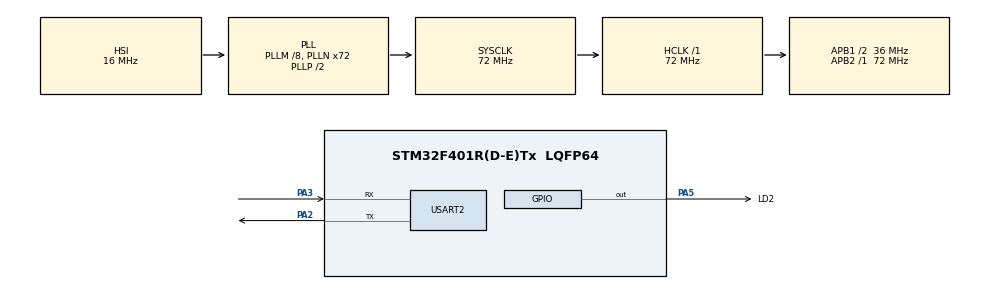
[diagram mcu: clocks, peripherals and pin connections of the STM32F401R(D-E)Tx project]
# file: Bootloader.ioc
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Mcu.Family=STM32F4
Mcu.Name=STM32F401R(D-E)Tx
Mcu.Package=LQFP64
NVIC.PriorityGroup=NVIC_PRIORITYGROUP_4
PA2.Mode=Asynchronous
PA2.Signal=USART2_TX
PA3.Mode=Asynchronous
PA3.Signal=USART2_RX
PA5.GPIO_Label=LD2
PA5.Signal=GPIO_Output
ProjectManager.HeapSize=0x200
ProjectManager.StackSize=0x400
ProjectManager.TargetToolchain=STM32CubeIDE
RCC.48MHZClocksFreq_Value=36000000
RCC.AHBFreq_Value=72000000
RCC.APB1CLKDivider=RCC_HCLK_DIV2
RCC.APB1Freq_Value=36000000
RCC.APB1TimFreq_Value=72000000
RCC.APB2Freq_Value=72000000
RCC.APB2TimFreq_Value=72000000
RCC.CortexFreq_Value=72000000
RCC.HCLKFreq_Value=72000000
RCC.HSE_VALUE=25000000
RCC.HSI_VALUE=16000000
RCC.LSE_VALUE=32768
RCC.PLLM=8
RCC.PLLN=72
RCC.SYSCLKFreq_VALUE=72000000
RCC.SYSCLKSource=RCC_SYSCLKSOURCE_PLLCLK
RCC.VCOOutputFreq_Value=144000000
USART2.VirtualMode=VM_ASYNC
board=custom

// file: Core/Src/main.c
/* USER CODE BEGIN Header */
/**
  ******************************************************************************
  * @file           : main.c
  * @brief          : Main program body
  ******************************************************************************
  * @attention
  *
  * Copyright (c) 2025 STMicroelectronics.
  * All rights reserved.
  *
  * This software is licensed under terms that can be found in the LICENSE file
  * in the root directory of this software component.
  * If no LICENSE file comes with this software, it is provided AS-IS.
  *
  ******************************************************************************
  */
/* USER CODE END Header */
#include "main.h"

/* USER CODE BEGIN Includes */
#include "stdio.h"
/* USER CODE END Includes */

/* USER CODE BEGIN PTD */
#define FLASH_APP_ADDR 	0x8008000
/* USER CODE END PTD */

UART_HandleTypeDef huart2;

/* USER CODE BEGIN PV */

_Bool Firmware_Completed_EOF=0;
uint32_t Current_Address= 0;
uint32_t Previous_Address =0;
uint16_t CRC_VALUE=0;
uint8_t Length =0;
uint8_t Uart_Rx[200];
uint8_t crc_data[2];
static FLASH_EraseInitTypeDef Erase;
/* Table of CRC values for high-order byte */
static const uint8_t table_crc_hi[] = {
    0x00, 0xC1, 0x81, 0x40, 0x01, 0xC0, 0x80, 0x41, 0x01, 0xC0,
    0x80, 0x41, 0x00, 0xC1, 0x81, 0x40, 0x01, 0xC0, 0x80, 0x41,
    0x00, 0xC1, 0x81, 0x40, 0x00, 0xC1, 0x81, 0x40, 0x01, 0xC0,
    0x80, 0x41, 0x01, 0xC0, 0x80, 0x41, 0x00, 0xC1, 0x81, 0x40,
    0x00, 0xC1, 0x81, 0x40, 0x01, 0xC0, 0x80, 0x41, 0x00, 0xC1,
    0x81, 0x40, 0x01, 0xC0, 0x80, 0x41, 0x01, 0xC0, 0x80, 0x41,
    0x00, 0xC1, 0x81, 0x40, 0x01, 0xC0, 0x80, 0x41, 0x00, 0xC1,
    0x81, 0x40, 0x00, 0xC1, 0x81, 0x40, 0x01, 0xC0, 0x80, 0x41,
    0x00, 0xC1, 0x81, 0x40, 0x01, 0xC0, 0x80, 0x41, 0x01, 0xC0,
    0x80, 0x41, 0x00, 0xC1, 0x81, 0x40, 0x00, 0xC1, 0x81, 0x40,
    0x01, 0xC0, 0x80, 0x41, 0x01, 0xC0, 0x80, 0x41, 0x00, 0xC1,
    0x81, 0x40, 0x01, 0xC0, 0x80, 0x41, 0x00, 0xC1, 0x81, 0x40,
    0x00, 0xC1, 0x81, 0x40, 0x01, 0xC0, 0x80, 0x41, 0x01, 0xC0,
    0x80, 0x41, 0x00, 0xC1, 0x81, 0x40, 0x00, 0xC1, 0x81, 0x40,
    0x01, 0xC0, 0x80, 0x41, 0x00, 0xC1, 0x81, 0x40, 0x01, 0xC0,
    0x80, 0x41, 0x01, 0xC0, 0x80, 0x41, 0x00, 0xC1, 0x81, 0x40,
    0x00, 0xC1, 0x81, 0x40, 0x01, 0xC0, 0x80, 0x41, 0x01, 0xC0,
    0x80, 0x41, 0x00, 0xC1, 0x81, 0x40, 0x01, 0xC0, 0x80, 0x41,
    0x00, 0xC1, 0x81, 0x40, 0x00, 0xC1, 0x81, 0x40, 0x01, 0xC0,
    0x80, 0x41, 0x00, 0xC1, 0x81, 0x40, 0x01, 0xC0, 0x80, 0x41,
    0x01, 0xC0, 0x80, 0x41, 0x00, 0xC1, 0x81, 0x40, 0x01, 0xC0,
    0x80, 0x41, 0x00, 0xC1, 0x81, 0x40, 0x00, 0xC1, 0x81, 0x40,
    0x01, 0xC0, 0x80, 0x41, 0x01, 0xC0, 0x80, 0x41, 0x00, 0xC1,
    0x81, 0x40, 0x00, 0xC1, 0x81, 0x40, 0x01, 0xC0, 0x80, 0x41,
    0x00, 0xC1, 0x81, 0x40, 0x01, 0xC0, 0x80, 0x41, 0x01, 0xC0,
    0x80, 0x41, 0x00, 0xC1, 0x81, 0x40
};

/* Table of CRC values for low-order byte */
static const uint8_t table_crc_lo[] = {
    0x00, 0xC0, 0xC1, 0x01, 0xC3, 0x03, 0x02, 0xC2, 0xC6, 0x06,
    0x07, 0xC7, 0x05, 0xC5, 0xC4, 0x04, 0xCC, 0x0C, 0x0D, 0xCD,
    0x0F, 0xCF, 0xCE, 0x0E, 0x0A, 0xCA, 0xCB, 0x0B, 0xC9, 0x09,
    0x08, 0xC8, 0xD8, 0x18, 0x19, 0xD9, 0x1B, 0xDB, 0xDA, 0x1A,
    0x1E, 0xDE, 0xDF, 0x1F, 0xDD, 0x1D, 0x1C, 0xDC, 0x14, 0xD4,
    0xD5, 0x15, 0xD7, 0x17, 0x16, 0xD6, 0xD2, 0x12, 0x13, 0xD3,
    0x11, 0xD1, 0xD0, 0x10, 0xF0, 0x30, 0x31, 0xF1, 0x33, 0xF3,
    0xF2, 0x32, 0x36, 0xF6, 0xF7, 0x37, 0xF5, 0x35, 0x34, 0xF4,
    0x3C, 0xFC, 0xFD, 0x3D, 0xFF, 0x3F, 0x3E, 0xFE, 0xFA, 0x3A,
    0x3B, 0xFB, 0x39, 0xF9, 0xF8, 0x38, 0x28, 0xE8, 0xE9, 0x29,
    0xEB, 0x2B, 0x2A, 0xEA, 0xEE, 0x2E, 0x2F, 0xEF, 0x2D, 0xED,
    0xEC, 0x2C, 0xE4, 0x24, 0x25, 0xE5, 0x27, 0xE7, 0xE6, 0x26,
    0x22, 0xE2, 0xE3, 0x23, 0xE1, 0x21, 0x20, 0xE0, 0xA0, 0x60,
    0x61, 0xA1, 0x63, 0xA3, 0xA2, 0x62, 0x66, 0xA6, 0xA7, 0x67,
    0xA5, 0x65, 0x64, 0xA4, 0x6C, 0xAC, 0xAD, 0x6D, 0xAF, 0x6F,
    0x6E, 0xAE, 0xAA, 0x6A, 0x6B, 0xAB, 0x69, 0xA9, 0xA8, 0x68,
    0x78, 0xB8, 0xB9, 0x79, 0xBB, 0x7B, 0x7A, 0xBA, 0xBE, 0x7E,
    0x7F, 0xBF, 0x7D, 0xBD, 0xBC, 0x7C, 0xB4, 0x74, 0x75, 0xB5,
    0x77, 0xB7, 0xB6, 0x76, 0x72, 0xB2, 0xB3, 0x73, 0xB1, 0x71,
    0x70, 0xB0, 0x50, 0x90, 0x91, 0x51, 0x93, 0x53, 0x52, 0x92,
    0x96, 0x56, 0x57, 0x97, 0x55, 0x95, 0x94, 0x54, 0x9C, 0x5C,
    0x5D, 0x9D, 0x5F, 0x9F, 0x9E, 0x5E, 0x5A, 0x9A, 0x9B, 0x5B,
    0x99, 0x59, 0x58, 0x98, 0x88, 0x48, 0x49, 0x89, 0x4B, 0x8B,
    0x8A, 0x4A, 0x4E, 0x8E, 0x8F, 0x4F, 0x8D, 0x4D, 0x4C, 0x8C,
    0x44, 0x84, 0x85, 0x45, 0x87, 0x47, 0x46, 0x86, 0x82, 0x42,
    0x43, 0x83, 0x41, 0x81, 0x80, 0x40
};
/* USER CODE END PV */

void SystemClock_Config(void);
static void MX_GPIO_Init(void);
static void MX_USART2_UART_Init(void);
/* USER CODE BEGIN PFP */
typedef void (*pFunction)(void);

#ifdef __GNUC__
#define PUTCHAR_PROTOTYPE int __io_putchar(int ch)
#else
#define PUTCHAR_PROTOTYPE int fputc(int ch, FILE *f)
#endif

PUTCHAR_PROTOTYPE
{
  HAL_UART_Transmit(&huart2, (uint8_t *)&ch, 1, HAL_MAX_DELAY);
  return ch;
}
/* USER CODE END PFP */

/* USER CODE BEGIN 0 */
void go2App(void)
{
	uint32_t JumpAddress;
	pFunction Jump_To_Application;

	printf("Bootloader Start \r\n");

	//Check if there is something installed in the app Flash Region
	if(((*(uint32_t * )FLASH_APP_ADDR)& 0x2FFE0000) == 0x20000000)
	{
		printf("App Start..\r\n");
		HAL_Delay(100);
		// jump to the application
		JumpAddress = *(uint32_t*)( FLASH_APP_ADDR + 4);
		Jump_To_Application = (pFunction) JumpAddress;
		//Initialize application's stack pointer
		__set_MSP(*(uint32_t *)FLASH_APP_ADDR);
		Jump_To_Application();
	}
	else{
		//there is no application is installed
		printf("No APP Found \r\n");
	}
}

uint32_t crc16(uint8_t *buffer, uint16_t buffer_length)
{
    uint8_t crc_hi = 0xFF; /* high CRC byte initialized */
    uint8_t crc_lo = 0xFF; /* low CRC byte initialized */
    uint16_t i; /* will index into CRC lookup */

    /* pass through message buffer */
    while (buffer_length--) {
        i = crc_lo ^ *buffer++; /* calculate the CRC  */
        crc_lo = crc_hi ^ table_crc_hi[i];
        crc_hi = table_crc_lo[i];
    }

    return (crc_hi << 8 | crc_lo);
}

static uint32_t GetSector(uint32_t Address)
{
  uint32_t sector = 0;

  if((Address < 0x08003FFF) && (Address >= 0x08000000))
  {
    sector = FLASH_SECTOR_0;
  }
  else if((Address < 0x08007FFF) && (Address >= 0x08004000))
  {
    sector = FLASH_SECTOR_1;
  }
  else if((Address < 0x0800BFFF) && (Address >= 0x08008000))
  {
    sector = FLASH_SECTOR_2;
  }
  else if((Address < 0x0800FFFF) && (Address >= 0x0800C000))
  {
    sector = FLASH_SECTOR_3;
  }
  else if((Address < 0x0801FFFF) && (Address >= 0x08010000))
  {
    sector = FLASH_SECTOR_4;
  }
  else if((Address < 0x0803FFFF) && (Address >= 0x08020000))
  {
    sector = FLASH_SECTOR_5;
  }
  else if((Address < 0x0805FFFF) && (Address >= 0x08040000))
  {
    sector = FLASH_SECTOR_6;
  }
  else if((Address < 0x0807FFFF) && (Address >= 0x08060000))
  {
    sector = FLASH_SECTOR_7;
  }
  return sector;
}

uint32_t Flash_Write_Data (uint32_t StartSectorAddress, uint32_t *Data, uint16_t numberofwords)
{

	static FLASH_EraseInitTypeDef EraseInitStruct;
	uint32_t SECTORError;
	int sofar=0;

	 /* Unlock the Flash to enable the flash control register access *************/
	  HAL_FLASH_Unlock();

	  /* Erase the user Flash area */

	  /* Get the number of sector to erase from 1st sector */

//	  uint32_t StartSector = GetSector(StartSectorAddress);
//	  uint32_t EndSectorAddress = StartSectorAddress + numberofwords*4;
//	  uint32_t EndSector = GetSector(EndSectorAddress);
//
//	  /* Fill EraseInit structure*/
//	  EraseInitStruct.TypeErase     = FLASH_TYPEERASE_SECTORS;
//	  EraseInitStruct.VoltageRange  = FLASH_VOLTAGE_RANGE_3;
//	  EraseInitStruct.Sector        = StartSector;
//	  EraseInitStruct.NbSectors     = (EndSector - StartSector) + 1;
//
//	  /* Note: If an erase operation in Flash memory also concerns data in the data or instruction cache,
//	     you have to make sure that these data are rewritten before they are accessed during code
//	     execution. If this cannot be done safely, it is recommended to flush the caches by setting the
//	     DCRST and ICRST bits in the FLASH_CR register. */
//	  if (HAL_FLASHEx_Erase(&EraseInitStruct, &SECTORError) != HAL_OK)
//	  {
//		  return HAL_FLASH_GetError ();
//	  }

	  /* Program the user Flash area word by word
	    (area defined by FLASH_USER_START_ADDR and FLASH_USER_END_ADDR) ***********/

	   while (sofar<(numberofwords/4))
	   {
	     if (HAL_FLASH_Program(FLASH_TYPEPROGRAM_WORD, StartSectorAddress, Data[sofar]) == HAL_OK)
	     {
	    	 StartSectorAddress += 4;  // use StartPageAddress += 2 for half word and 8 for double word
	    	 sofar++;
	     }
	     else
	     {
	       /* Error occurred while writing data in Flash memory*/
	    	 return HAL_FLASH_GetError ();
	     }
	   }

	  /* Lock the Flash to disable the flash control register access (recommended
	     to protect the FLASH memory against possible unwanted operation) *********/
	  HAL_FLASH_Lock();

	   return 0;
}

uint32_t Erase_All_Sector(void)
{
	static  FLASH_EraseInitTypeDef EraseInitStruct;
	uint32_t SECTORError;

	HAL_FLASH_Unlock();

	EraseInitStruct.TypeErase    = FLASH_TYPEERASE_SECTORS;
	EraseInitStruct.VoltageRange = FLASH_VOLTAGE_RANGE_3;
	EraseInitStruct.Sector 	     = FLASH_SECTOR_2;
    EraseInitStruct.NbSectors    = FLASH_SECTOR_5 - FLASH_SECTOR_2;

	  if (HAL_FLASHEx_Erase(&EraseInitStruct, &SECTORError) != HAL_OK)
	  {
		  return HAL_FLASH_GetError ();
	  }

	  HAL_FLASH_Lock();

	  return 0;

}
/* USER CODE END 0 */

int main(void)
{

  /* MCU Configuration--------------------------------------------------------*/

  /* Reset of all peripherals, Initializes the Flash interface and the Systick. */

	HAL_Init();

  /* Configure the system clock */
  SystemClock_Config();

  /* Initialize all configured peripherals */
  MX_GPIO_Init();
  MX_USART2_UART_Init();
  /* USER CODE BEGIN 2 */
  uint8_t Buffer[] = {1,3};
  HAL_UART_Transmit(&huart2,Buffer , sizeof(Buffer)/sizeof(uint8_t), HAL_MAX_DELAY);
  HAL_UART_Receive(&huart2, Uart_Rx, 2, HAL_MAX_DELAY);
 // HAL_UART_Transmit(&huart2,Buffer , sizeof(Buffer)/sizeof(uint8_t), HAL_MAX_DELAY);
  if((Uart_Rx[0]== 0x01 )&&( Uart_Rx[1] == 0x03))
  {
	  Firmware_Completed_EOF = 0;
	 //
	  Current_Address = FLASH_APP_ADDR;
  }
  else
  {
	  Firmware_Completed_EOF = 1;
  }
  /* USER CODE END 2 */

  /* Infinite loop */
  while (1)
  {

    /* USER CODE BEGIN 3 */
#if 1
  if(Firmware_Completed_EOF== 0)
  {
	 HAL_UART_Receive(&huart2, &Length, 1, HAL_MAX_DELAY);
	 HAL_UART_Receive(&huart2, Uart_Rx, Length, HAL_MAX_DELAY);
     HAL_UART_Receive(&huart2, crc_data, 2, HAL_MAX_DELAY);
     CRC_VALUE = crc16(Uart_Rx,Length);
    if(CRC_VALUE == ((crc_data[0] << 0x08)|(crc_data[1])))
    {
#if 0
    	Previous_Address= Current_Address;
    	Flash_Write_Data(Current_Address, Uart_Rx, 198);
    	Current_Address+198;
#endif
        if((Uart_Rx[0]== 'E') && (Uart_Rx[1]== 'O') && (Uart_Rx[2]== 'F'))
        {
        	Firmware_Completed_EOF = 1;
            Buffer[0]= Buffer[1] = 0xEF;
      	    HAL_UART_Transmit(&huart2,Buffer , sizeof(Buffer)/sizeof(uint8_t), HAL_MAX_DELAY);
      	    Buffer[0]= Buffer[1] = 0x00;
        }
        else{
//          if((*(__IO uint32_t *) FLASH_APP_ADDR) != 0xFFFFFFFF)
//          {
//        	  Erase_All_Sector();
//          }
          Buffer[0]= Buffer[1] = 0xFF;
    	  Previous_Address = Current_Address;
    	  Flash_Write_Data(Current_Address,Uart_Rx,Length);
          Current_Address += Length;
          memset(Uart_Rx,'\0',Length);
    	  HAL_UART_Transmit(&huart2,Buffer , sizeof(Buffer)/sizeof(uint8_t), HAL_MAX_DELAY);
    	  Buffer[0]= Buffer[1] = 0x00;
        }
    }

  }else
	{
	  go2App();
	}
  }
#endif
  /* USER CODE END 3 */
}

void SystemClock_Config(void)
{
  RCC_OscInitTypeDef RCC_OscInitStruct = {0};
  RCC_ClkInitTypeDef RCC_ClkInitStruct = {0};

  /** Configure the main internal regulator output voltage
  */
  __HAL_RCC_PWR_CLK_ENABLE();
  __HAL_PWR_VOLTAGESCALING_CONFIG(PWR_REGULATOR_VOLTAGE_SCALE2);

  /** Initializes the RCC Oscillators according to the specified parameters
  * in the RCC_OscInitTypeDef structure.
  */
  RCC_OscInitStruct.OscillatorType = RCC_OSCILLATORTYPE_HSI;
  RCC_OscInitStruct.HSIState = RCC_HSI_ON;
  RCC_OscInitStruct.HSICalibrationValue = RCC_HSICALIBRATION_DEFAULT;
  RCC_OscInitStruct.PLL.PLLState = RCC_PLL_ON;
  RCC_OscInitStruct.PLL.PLLSource = RCC_PLLSOURCE_HSI;
  RCC_OscInitStruct.PLL.PLLM = 8;
  RCC_OscInitStruct.PLL.PLLN = 72;
  RCC_OscInitStruct.PLL.PLLP = RCC_PLLP_DIV2;
  RCC_OscInitStruct.PLL.PLLQ = 4;
  if (HAL_RCC_OscConfig(&RCC_OscInitStruct) != HAL_OK)
  {
    Error_Handler();
  }

  /** Initializes the CPU, AHB and APB buses clocks
  */
  RCC_ClkInitStruct.ClockType = RCC_CLOCKTYPE_HCLK|RCC_CLOCKTYPE_SYSCLK
                              |RCC_CLOCKTYPE_PCLK1|RCC_CLOCKTYPE_PCLK2;
  RCC_ClkInitStruct.SYSCLKSource = RCC_SYSCLKSOURCE_PLLCLK;
  RCC_ClkInitStruct.AHBCLKDivider = RCC_SYSCLK_DIV1;
  RCC_ClkInitStruct.APB1CLKDivider = RCC_HCLK_DIV2;
  RCC_ClkInitStruct.APB2CLKDivider = RCC_HCLK_DIV1;

  if (HAL_RCC_ClockConfig(&RCC_ClkInitStruct, FLASH_LATENCY_2) != HAL_OK)
  {
    Error_Handler();
  }
}

static void MX_USART2_UART_Init(void)
{

  huart2.Instance = USART2;
  huart2.Init.BaudRate = 115200;
  huart2.Init.WordLength = UART_WORDLENGTH_8B;
  huart2.Init.StopBits = UART_STOPBITS_1;
  huart2.Init.Parity = UART_PARITY_NONE;
  huart2.Init.Mode = UART_MODE_TX_RX;
  huart2.Init.HwFlowCtl = UART_HWCONTROL_NONE;
  huart2.Init.OverSampling = UART_OVERSAMPLING_16;
  if (HAL_UART_Init(&huart2) != HAL_OK)
  {
    Error_Handler();
  }

}

static void MX_GPIO_Init(void)
{
  GPIO_InitTypeDef GPIO_InitStruct = {0};

  /* GPIO Ports Clock Enable */
  __HAL_RCC_GPIOA_CLK_ENABLE();

  /*Configure GPIO pin Output Level */
  HAL_GPIO_WritePin(LD2_GPIO_Port, LD2_Pin, GPIO_PIN_RESET);

  /*Configure GPIO pin : LD2_Pin */
  GPIO_InitStruct.Pin = LD2_Pin;
  GPIO_InitStruct.Mode = GPIO_MODE_OUTPUT_PP;
  GPIO_InitStruct.Pull = GPIO_NOPULL;
  GPIO_InitStruct.Speed = GPIO_SPEED_FREQ_LOW;
  HAL_GPIO_Init(LD2_GPIO_Port, &GPIO_InitStruct);

}

void Error_Handler(void)
{
  __disable_irq();
  while (1)
  {
  }
}
